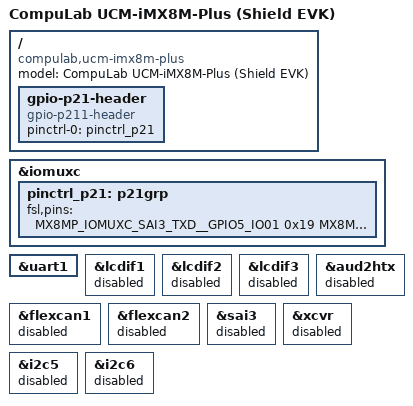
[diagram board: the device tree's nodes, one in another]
// SPDX-License-Identifier: (GPL-2.0+ OR MIT)
/*
 * Copyright 2021 CompuLab
 */

/dts-v1/;

#include "ucm-imx8m-plus.dts"

/ {
	model = "CompuLab UCM-iMX8M-Plus (Shield EVK)";
	compatible = "compulab,ucm-imx8m-plus", "fsl,imx8mp";

	gpio-p21-header {
		compatible = "gpio-p211-header";
		pinctrl-names = "default";
		pinctrl-0 = <&pinctrl_p21>;
		status = "okay";
	};
};


/* PIN RE-ROUTING */
&iomuxc {
	pinctrl_p21: p21grp {
		fsl,pins = <
			MX8MP_IOMUXC_SAI3_TXD__GPIO5_IO01	0x19 /* P21-11; GPIO=(32*(5-1)+1)=129 */
			MX8MP_IOMUXC_SAI3_TXC__GPIO5_IO00	0x19 /* P21-13; GPIO=(32*(5-1)+0)=128 */
			MX8MP_IOMUXC_SAI3_MCLK__GPIO5_IO02	0x19 /* P21-15; GPIO=(32*(5-1)+2)=130 */
			MX8MP_IOMUXC_SAI3_RXD__GPIO4_IO30	0x19 /* P21-17; GPIO=(32*(4-1)+30)=126 */
			MX8MP_IOMUXC_SAI3_RXC__GPIO4_IO29	0x19 /* P21-19; GPIO=(32*(4-1)+29)=125 */
			MX8MP_IOMUXC_SAI3_TXFS__GPIO4_IO31	0x19 /* P21-21; GPIO=(32*(4-1)+31)=127 */
			MX8MP_IOMUXC_SAI3_RXFS__GPIO4_IO28	0x19 /* P21-23; GPIO=(32*(4-1)+28)=124 */
		>;
	};
};

/* ENABLED PERIPHERALS */

&uart1 {
	status = "okay";
};

/* DISABLED PERIPHERALS */

/* mipi dsi */
&lcdif1 {
	status = "disabled";
};

/* lvds */
&lcdif2 {
	status = "disabled";
};

/* hdmi */
&lcdif3 {
	status = "disabled";
};

&aud2htx {
	status = "disabled";
};

&flexcan1 {
	status = "disabled";
};

&flexcan2 {
	status = "disabled";
};

&sai3 {
	status = "disabled";
};

&xcvr {
	status = "disabled";
};

&i2c5 {
	status = "disabled";
};

&i2c6 {
	status = "disabled";
};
